VERSION ""

NS_ :

BS_:

BU_: Acquisition_Board2 Acquisition_Board3 Acquisition_Board5 Acquisition_Board6 Acquisition_Board7 Acquisition_Board8 VCU PDM BMS ICD Data_Station Acquisition_Board1

BO_ 3221225472 VECTOR__INDEPENDENT_SIG_MSG: 0 Vector__XXX
 SG_ NewSignal_0017 : 32|8@1+ (1,0) [0|0] "" Vector__XXX
 SG_ NewSignal_0016 : 48|16@1+ (0.1,0) [0|0] "" Vector__XXX
 SG_ SUSP_R : 0|16@1+ (0.1,0) [0|0] "mm" Vector__XXX
 SG_ SUSP_L : 16|16@1+ (0.1,0) [0|0] "mm" Vector__XXX
 SG_ NTC_3 : 32|16@1- (0.1,0) [0|0] "ºC" Vector__XXX
 SG_ SPD_WHEEL : 0|16@1+ (0.1,0) [0|0] "km/h" Vector__XXX
 SG_ SPD_WHEEL : 0|16@1+ (0.1,0) [0|0] "km/h" Vector__XXX
 SG_ SPD_WHEEL : 0|16@1+ (0.1,0) [0|0] "km/h" Vector__XXX
 SG_ SPD_WHEEL : 0|16@1+ (0.1,0) [0|0] "km/h" Vector__XXX
 SG_ TIRE_TEMP : 0|16@1- (0.1,0) [0|0] "ºC"  Data_Station
 SG_ BRAKE_TEMP : 16|16@1- (0.1,0) [0|0] "ºC"  Data_Station
 SG_ TIRE_TEMP : 0|16@1- (0.1,0) [0|0] "ºC"  Data_Station
 SG_ BRAKE_TEMP : 16|16@1- (0.1,0) [0|0] "ºC"  Data_Station
 SG_ TIRE_TEMP : 0|16@1- (0.1,0) [0|0] "ºC"  Data_Station
 SG_ BRAKE_TEMP : 16|16@1- (0.1,0) [0|0] "ºC"  Data_Station

BO_ 48 AQT2: 4 Acquisition_Board2
 SG_ FRONT_LEFT_WHEEL_RPM : 0|16@1+ (1,0) [0|0] "RPM"  Data_Station
 SG_ FRONT_RIGHT_WHEEL_RPM : 16|16@1+ (1,0) [0|0] "RPM"  Data_Station

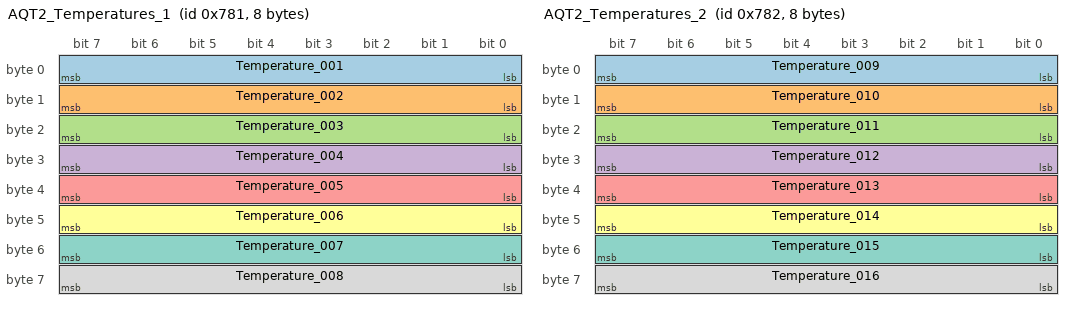
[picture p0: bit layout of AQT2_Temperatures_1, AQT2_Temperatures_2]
BO_ 1921 AQT2_Temperatures_1: 8 Acquisition_Board2
 SG_ Temperature_001 : 0|8@1+ (1,30) [30|285] "degC"  Data_Station
 SG_ Temperature_002 : 8|8@1+ (1,30) [30|285] "degC"  Data_Station
 SG_ Temperature_003 : 16|8@1+ (1,30) [30|285] "degC"  Data_Station
 SG_ Temperature_004 : 24|8@1+ (1,30) [30|285] "degC"  Data_Station
 SG_ Temperature_005 : 32|8@1+ (1,30) [30|285] "degC"  Data_Station
 SG_ Temperature_006 : 40|8@1+ (1,30) [30|285] "degC"  Data_Station
 SG_ Temperature_007 : 48|8@1+ (1,30) [30|285] "degC"  Data_Station
 SG_ Temperature_008 : 56|8@1+ (1,30) [30|285] "degC"  Data_Station

BO_ 1922 AQT2_Temperatures_2: 8 Acquisition_Board2
 SG_ Temperature_009 : 0|8@1+ (1,30) [30|285] "degC"  Data_Station
 SG_ Temperature_010 : 8|8@1+ (1,30) [30|285] "degC"  Data_Station
 SG_ Temperature_011 : 16|8@1+ (1,30) [30|285] "degC"  Data_Station
 SG_ Temperature_012 : 24|8@1+ (1,30) [30|285] "degC"  Data_Station
 SG_ Temperature_013 : 32|8@1+ (1,30) [30|285] "degC"  Data_Station
 SG_ Temperature_014 : 40|8@1+ (1,30) [30|285] "degC"  Data_Station
 SG_ Temperature_015 : 48|8@1+ (1,30) [30|285] "degC"  Data_Station
 SG_ Temperature_016 : 56|8@1+ (1,30) [30|285] "degC"  Data_Station

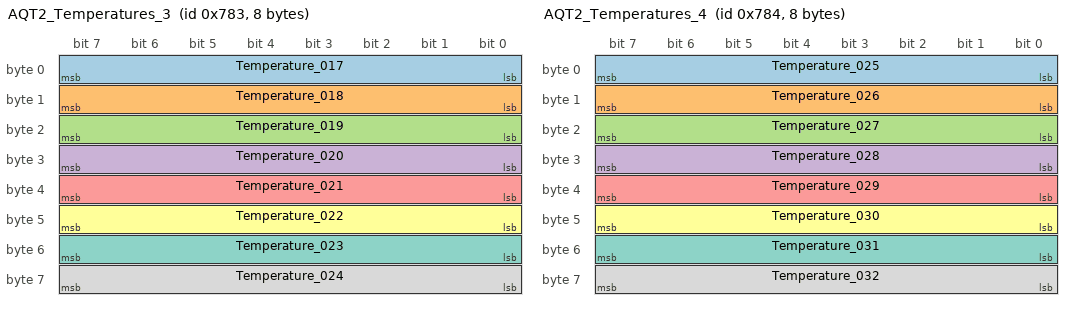
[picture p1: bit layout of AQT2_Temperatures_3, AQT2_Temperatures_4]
BO_ 1923 AQT2_Temperatures_3: 8 Acquisition_Board2
 SG_ Temperature_017 : 0|8@1+ (1,30) [30|285] "degC"  Data_Station
 SG_ Temperature_018 : 8|8@1+ (1,30) [30|285] "degC"  Data_Station
 SG_ Temperature_019 : 16|8@1+ (1,30) [30|285] "degC"  Data_Station
 SG_ Temperature_020 : 24|8@1+ (1,30) [30|285] "degC"  Data_Station
 SG_ Temperature_021 : 32|8@1+ (1,30) [30|285] "degC"  Data_Station
 SG_ Temperature_022 : 40|8@1+ (1,30) [30|285] "degC"  Data_Station
 SG_ Temperature_023 : 48|8@1+ (1,30) [30|285] "degC"  Data_Station
 SG_ Temperature_024 : 56|8@1+ (1,30) [30|285] "degC"  Data_Station

BO_ 1924 AQT2_Temperatures_4: 8 Acquisition_Board2
 SG_ Temperature_025 : 0|8@1+ (1,30) [30|285] "degC"  Data_Station
 SG_ Temperature_026 : 8|8@1+ (1,30) [30|285] "degC"  Data_Station
 SG_ Temperature_027 : 16|8@1+ (1,30) [30|285] "degC"  Data_Station
 SG_ Temperature_028 : 24|8@1+ (1,30) [30|285] "degC"  Data_Station
 SG_ Temperature_029 : 32|8@1+ (1,30) [30|285] "degC"  Data_Station
 SG_ Temperature_030 : 40|8@1+ (1,30) [30|285] "degC"  Data_Station
 SG_ Temperature_031 : 48|8@1+ (1,30) [30|285] "degC"  Data_Station
 SG_ Temperature_032 : 56|8@1+ (1,30) [30|285] "degC"  Data_Station

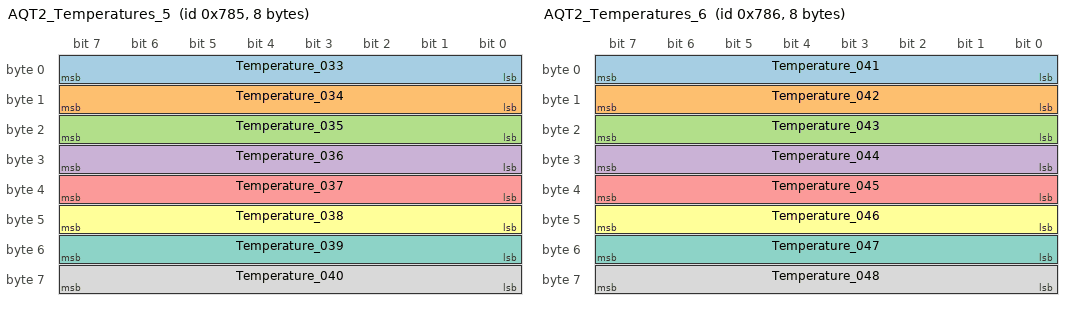
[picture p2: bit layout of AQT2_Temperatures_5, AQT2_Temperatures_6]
BO_ 1925 AQT2_Temperatures_5: 8 Acquisition_Board2
 SG_ Temperature_033 : 0|8@1+ (1,30) [30|285] "degC"  Data_Station
 SG_ Temperature_034 : 8|8@1+ (1,30) [30|285] "degC"  Data_Station
 SG_ Temperature_035 : 16|8@1+ (1,30) [30|285] "degC"  Data_Station
 SG_ Temperature_036 : 24|8@1+ (1,30) [30|285] "degC"  Data_Station
 SG_ Temperature_037 : 32|8@1+ (1,30) [30|285] "degC"  Data_Station
 SG_ Temperature_038 : 40|8@1+ (1,30) [30|285] "degC"  Data_Station
 SG_ Temperature_039 : 48|8@1+ (1,30) [30|285] "degC"  Data_Station
 SG_ Temperature_040 : 56|8@1+ (1,30) [30|285] "degC"  Data_Station

BO_ 1926 AQT2_Temperatures_6: 8 Acquisition_Board2
 SG_ Temperature_041 : 0|8@1+ (1,30) [30|285] "degC"  Data_Station
 SG_ Temperature_042 : 8|8@1+ (1,30) [30|285] "degC"  Data_Station
 SG_ Temperature_043 : 16|8@1+ (1,30) [30|285] "degC"  Data_Station
 SG_ Temperature_044 : 24|8@1+ (1,30) [30|285] "degC"  Data_Station
 SG_ Temperature_045 : 32|8@1+ (1,30) [30|285] "degC"  Data_Station
 SG_ Temperature_046 : 40|8@1+ (1,30) [30|285] "degC"  Data_Station
 SG_ Temperature_047 : 48|8@1+ (1,30) [30|285] "degC"  Data_Station
 SG_ Temperature_048 : 56|8@1+ (1,30) [30|285] "degC"  Data_Station

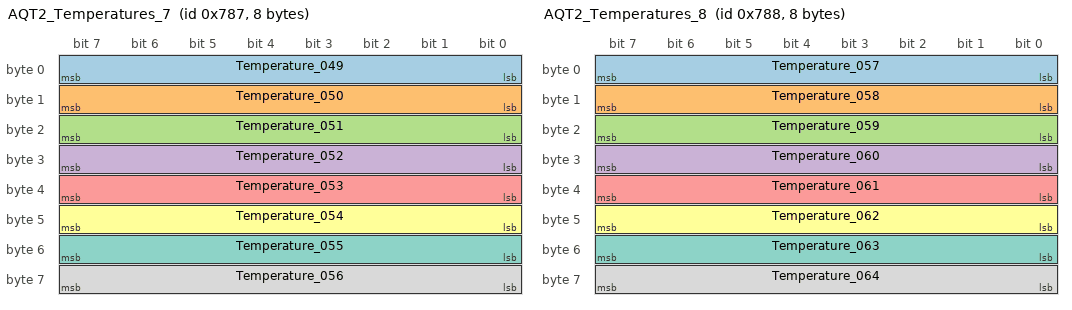
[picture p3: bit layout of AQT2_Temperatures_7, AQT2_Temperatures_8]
BO_ 1927 AQT2_Temperatures_7: 8 Acquisition_Board2
 SG_ Temperature_049 : 0|8@1+ (1,30) [30|285] "degC"  Data_Station
 SG_ Temperature_050 : 8|8@1+ (1,30) [30|285] "degC"  Data_Station
 SG_ Temperature_051 : 16|8@1+ (1,30) [30|285] "degC"  Data_Station
 SG_ Temperature_052 : 24|8@1+ (1,30) [30|285] "degC"  Data_Station
 SG_ Temperature_053 : 32|8@1+ (1,30) [30|285] "degC"  Data_Station
 SG_ Temperature_054 : 40|8@1+ (1,30) [30|285] "degC"  Data_Station
 SG_ Temperature_055 : 48|8@1+ (1,30) [30|285] "degC"  Data_Station
 SG_ Temperature_056 : 56|8@1+ (1,30) [30|285] "degC"  Data_Station

BO_ 1928 AQT2_Temperatures_8: 8 Acquisition_Board2
 SG_ Temperature_057 : 0|8@1+ (1,30) [30|285] "degC"  Data_Station
 SG_ Temperature_058 : 8|8@1+ (1,30) [30|285] "degC"  Data_Station
 SG_ Temperature_059 : 16|8@1+ (1,30) [30|285] "degC"  Data_Station
 SG_ Temperature_060 : 24|8@1+ (1,30) [30|285] "degC"  Data_Station
 SG_ Temperature_061 : 32|8@1+ (1,30) [30|285] "degC"  Data_Station
 SG_ Temperature_062 : 40|8@1+ (1,30) [30|285] "degC"  Data_Station
 SG_ Temperature_063 : 48|8@1+ (1,30) [30|285] "degC"  Data_Station
 SG_ Temperature_064 : 56|8@1+ (1,30) [30|285] "degC"  Data_Station

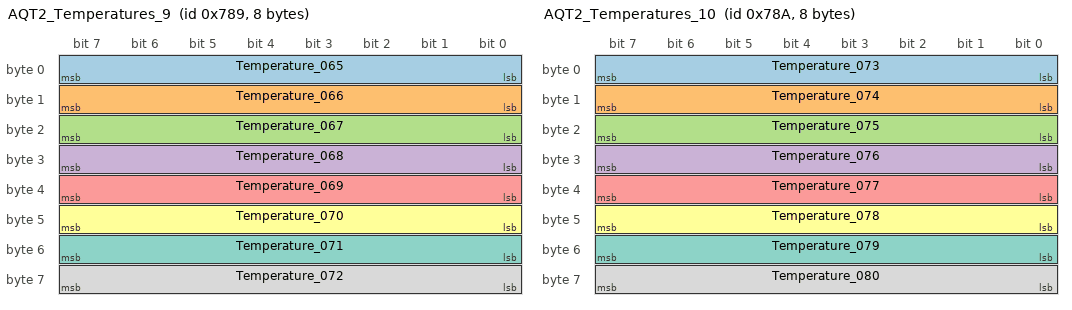
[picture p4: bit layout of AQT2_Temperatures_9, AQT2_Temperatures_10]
BO_ 1929 AQT2_Temperatures_9: 8 Acquisition_Board2
 SG_ Temperature_065 : 0|8@1+ (1,30) [30|285] "degC"  Data_Station
 SG_ Temperature_066 : 8|8@1+ (1,30) [30|285] "degC"  Data_Station
 SG_ Temperature_067 : 16|8@1+ (1,30) [30|285] "degC"  Data_Station
 SG_ Temperature_068 : 24|8@1+ (1,30) [30|285] "degC"  Data_Station
 SG_ Temperature_069 : 32|8@1+ (1,30) [30|285] "degC"  Data_Station
 SG_ Temperature_070 : 40|8@1+ (1,30) [30|285] "degC"  Data_Station
 SG_ Temperature_071 : 48|8@1+ (1,30) [30|285] "degC"  Data_Station
 SG_ Temperature_072 : 56|8@1+ (1,30) [30|285] "degC"  Data_Station

BO_ 1930 AQT2_Temperatures_10: 8 Acquisition_Board2
 SG_ Temperature_073 : 0|8@1+ (1,30) [30|285] "degC"  Data_Station
 SG_ Temperature_074 : 8|8@1+ (1,30) [30|285] "degC"  Data_Station
 SG_ Temperature_075 : 16|8@1+ (1,30) [30|285] "degC"  Data_Station
 SG_ Temperature_076 : 24|8@1+ (1,30) [30|285] "degC"  Data_Station
 SG_ Temperature_077 : 32|8@1+ (1,30) [30|285] "degC"  Data_Station
 SG_ Temperature_078 : 40|8@1+ (1,30) [30|285] "degC"  Data_Station
 SG_ Temperature_079 : 48|8@1+ (1,30) [30|285] "degC"  Data_Station
 SG_ Temperature_080 : 56|8@1+ (1,30) [30|285] "degC"  Data_Station

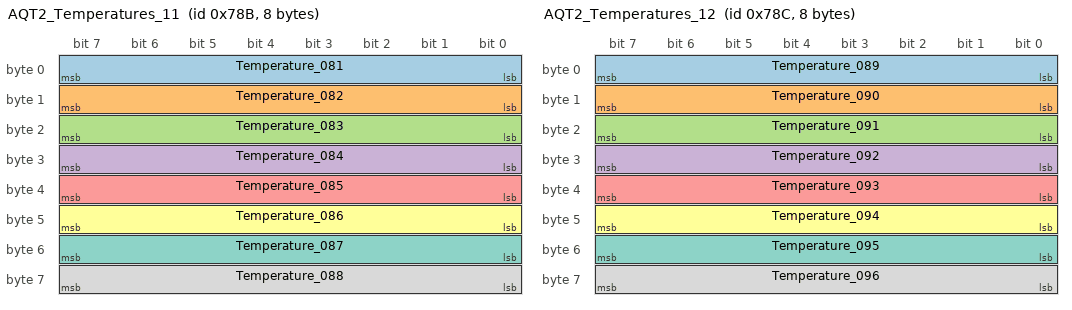
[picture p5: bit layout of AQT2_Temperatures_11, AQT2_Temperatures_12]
BO_ 1931 AQT2_Temperatures_11: 8 Acquisition_Board2
 SG_ Temperature_081 : 0|8@1+ (1,30) [30|285] "degC"  Data_Station
 SG_ Temperature_082 : 8|8@1+ (1,30) [30|285] "degC"  Data_Station
 SG_ Temperature_083 : 16|8@1+ (1,30) [30|285] "degC"  Data_Station
 SG_ Temperature_084 : 24|8@1+ (1,30) [30|285] "degC"  Data_Station
 SG_ Temperature_085 : 32|8@1+ (1,30) [30|285] "degC"  Data_Station
 SG_ Temperature_086 : 40|8@1+ (1,30) [30|285] "degC"  Data_Station
 SG_ Temperature_087 : 48|8@1+ (1,30) [30|285] "degC"  Data_Station
 SG_ Temperature_088 : 56|8@1+ (1,30) [30|285] "degC"  Data_Station

BO_ 1932 AQT2_Temperatures_12: 8 Acquisition_Board2
 SG_ Temperature_089 : 0|8@1+ (1,30) [30|285] "degC"  Data_Station
 SG_ Temperature_090 : 8|8@1+ (1,30) [30|285] "degC"  Data_Station
 SG_ Temperature_091 : 16|8@1+ (1,30) [30|285] "degC"  Data_Station
 SG_ Temperature_092 : 24|8@1+ (1,30) [30|285] "degC"  Data_Station
 SG_ Temperature_093 : 32|8@1+ (1,30) [30|285] "degC"  Data_Station
 SG_ Temperature_094 : 40|8@1+ (1,30) [30|285] "degC"  Data_Station
 SG_ Temperature_095 : 48|8@1+ (1,30) [30|285] "degC"  Data_Station
 SG_ Temperature_096 : 56|8@1+ (1,30) [30|285] "degC"  Data_Station

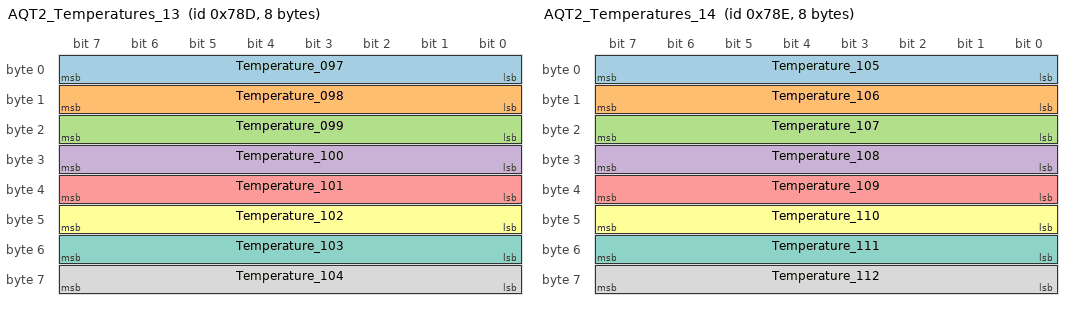
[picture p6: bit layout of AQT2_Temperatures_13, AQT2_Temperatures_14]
BO_ 1933 AQT2_Temperatures_13: 8 Acquisition_Board2
 SG_ Temperature_097 : 0|8@1+ (1,30) [30|285] "degC"  Data_Station
 SG_ Temperature_098 : 8|8@1+ (1,30) [30|285] "degC"  Data_Station
 SG_ Temperature_099 : 16|8@1+ (1,30) [30|285] "degC"  Data_Station
 SG_ Temperature_100 : 24|8@1+ (1,30) [30|285] "degC"  Data_Station
 SG_ Temperature_101 : 32|8@1+ (1,30) [30|285] "degC"  Data_Station
 SG_ Temperature_102 : 40|8@1+ (1,30) [30|285] "degC"  Data_Station
 SG_ Temperature_103 : 48|8@1+ (1,30) [30|285] "degC"  Data_Station
 SG_ Temperature_104 : 56|8@1+ (1,30) [30|285] "degC"  Data_Station

BO_ 1934 AQT2_Temperatures_14: 8 Acquisition_Board2
 SG_ Temperature_105 : 0|8@1+ (1,30) [30|285] "degC"  Data_Station
 SG_ Temperature_106 : 8|8@1+ (1,30) [30|285] "degC"  Data_Station
 SG_ Temperature_107 : 16|8@1+ (1,30) [30|285] "degC"  Data_Station
 SG_ Temperature_108 : 24|8@1+ (1,30) [30|285] "degC"  Data_Station
 SG_ Temperature_109 : 32|8@1+ (1,30) [30|285] "degC"  Data_Station
 SG_ Temperature_110 : 40|8@1+ (1,30) [30|285] "degC"  Data_Station
 SG_ Temperature_111 : 48|8@1+ (1,30) [30|285] "degC"  Data_Station
 SG_ Temperature_112 : 56|8@1+ (1,30) [30|285] "degC"  Data_Station

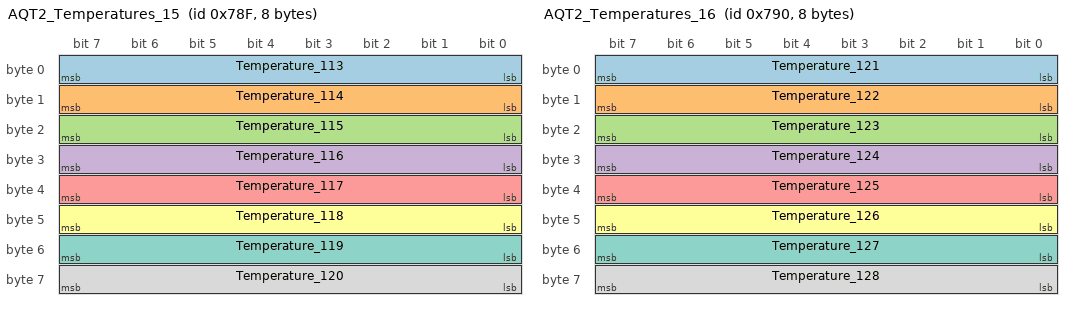
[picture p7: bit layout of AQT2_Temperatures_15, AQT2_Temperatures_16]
BO_ 1935 AQT2_Temperatures_15: 8 Acquisition_Board2
 SG_ Temperature_113 : 0|8@1+ (1,30) [30|285] "degC"  Data_Station
 SG_ Temperature_114 : 8|8@1+ (1,30) [30|285] "degC"  Data_Station
 SG_ Temperature_115 : 16|8@1+ (1,30) [30|285] "degC"  Data_Station
 SG_ Temperature_116 : 24|8@1+ (1,30) [30|285] "degC"  Data_Station
 SG_ Temperature_117 : 32|8@1+ (1,30) [30|285] "degC"  Data_Station
 SG_ Temperature_118 : 40|8@1+ (1,30) [30|285] "degC"  Data_Station
 SG_ Temperature_119 : 48|8@1+ (1,30) [30|285] "degC"  Data_Station
 SG_ Temperature_120 : 56|8@1+ (1,30) [30|285] "degC"  Data_Station

BO_ 1936 AQT2_Temperatures_16: 8 Acquisition_Board2
 SG_ Temperature_121 : 0|8@1+ (1,30) [30|285] "degC"  Data_Station
 SG_ Temperature_122 : 8|8@1+ (1,30) [30|285] "degC"  Data_Station
 SG_ Temperature_123 : 16|8@1+ (1,30) [30|285] "degC"  Data_Station
 SG_ Temperature_124 : 24|8@1+ (1,30) [30|285] "degC"  Data_Station
 SG_ Temperature_125 : 32|8@1+ (1,30) [30|285] "degC"  Data_Station
 SG_ Temperature_126 : 40|8@1+ (1,30) [30|285] "degC"  Data_Station
 SG_ Temperature_127 : 48|8@1+ (1,30) [30|285] "degC"  Data_Station
 SG_ Temperature_128 : 56|8@1+ (1,30) [30|285] "degC"  Data_Station

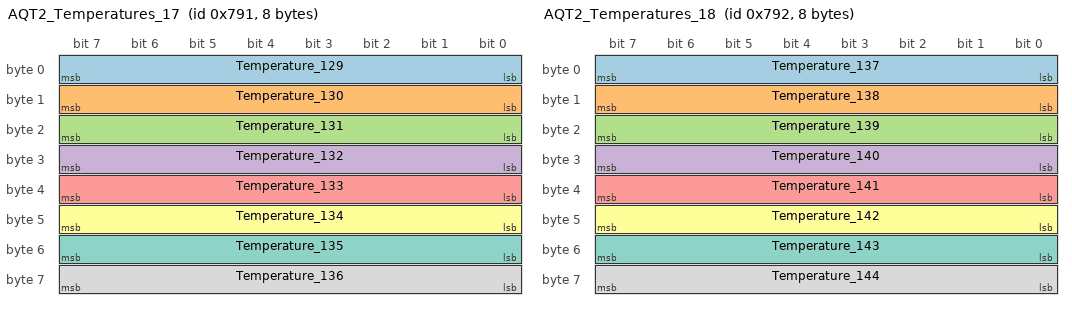
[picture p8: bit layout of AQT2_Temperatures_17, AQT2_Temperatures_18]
BO_ 1937 AQT2_Temperatures_17: 8 Acquisition_Board2
 SG_ Temperature_129 : 0|8@1+ (1,30) [30|285] "degC"  Data_Station
 SG_ Temperature_130 : 8|8@1+ (1,30) [30|285] "degC"  Data_Station
 SG_ Temperature_131 : 16|8@1+ (1,30) [30|285] "degC"  Data_Station
 SG_ Temperature_132 : 24|8@1+ (1,30) [30|285] "degC"  Data_Station
 SG_ Temperature_133 : 32|8@1+ (1,30) [30|285] "degC"  Data_Station
 SG_ Temperature_134 : 40|8@1+ (1,30) [30|285] "degC"  Data_Station
 SG_ Temperature_135 : 48|8@1+ (1,30) [30|285] "degC"  Data_Station
 SG_ Temperature_136 : 56|8@1+ (1,30) [30|285] "degC"  Data_Station

BO_ 1938 AQT2_Temperatures_18: 8 Acquisition_Board2
 SG_ Temperature_137 : 0|8@1+ (1,30) [30|285] "degC"  Data_Station
 SG_ Temperature_138 : 8|8@1+ (1,30) [30|285] "degC"  Data_Station
 SG_ Temperature_139 : 16|8@1+ (1,30) [30|285] "degC"  Data_Station
 SG_ Temperature_140 : 24|8@1+ (1,30) [30|285] "degC"  Data_Station
 SG_ Temperature_141 : 32|8@1+ (1,30) [30|285] "degC"  Data_Station
 SG_ Temperature_142 : 40|8@1+ (1,30) [30|285] "degC"  Data_Station
 SG_ Temperature_143 : 48|8@1+ (1,30) [30|285] "degC"  Data_Station
 SG_ Temperature_144 : 56|8@1+ (1,30) [30|285] "degC"  Data_Station

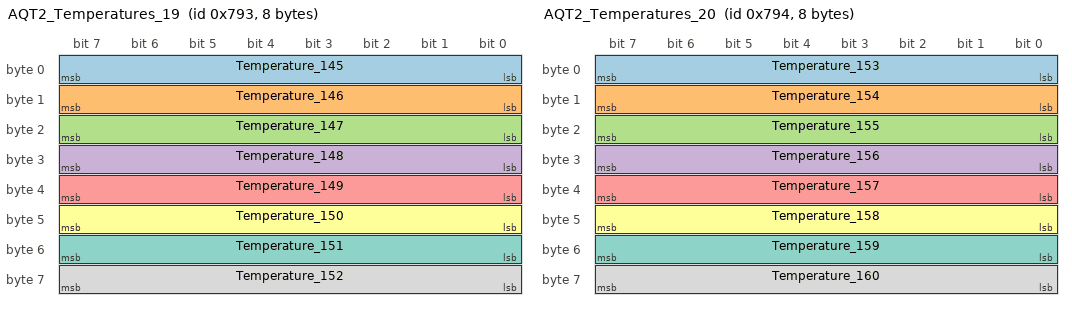
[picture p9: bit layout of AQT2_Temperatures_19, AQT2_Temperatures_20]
BO_ 1939 AQT2_Temperatures_19: 8 Acquisition_Board2
 SG_ Temperature_145 : 0|8@1+ (1,30) [30|285] "degC"  Data_Station
 SG_ Temperature_146 : 8|8@1+ (1,30) [30|285] "degC"  Data_Station
 SG_ Temperature_147 : 16|8@1+ (1,30) [30|285] "degC"  Data_Station
 SG_ Temperature_148 : 24|8@1+ (1,30) [30|285] "degC"  Data_Station
 SG_ Temperature_149 : 32|8@1+ (1,30) [30|285] "degC"  Data_Station
 SG_ Temperature_150 : 40|8@1+ (1,30) [30|285] "degC"  Data_Station
 SG_ Temperature_151 : 48|8@1+ (1,30) [30|285] "degC"  Data_Station
 SG_ Temperature_152 : 56|8@1+ (1,30) [30|285] "degC"  Data_Station

BO_ 1940 AQT2_Temperatures_20: 8 Acquisition_Board2
 SG_ Temperature_153 : 0|8@1+ (1,30) [30|285] "degC"  Data_Station
 SG_ Temperature_154 : 8|8@1+ (1,30) [30|285] "degC"  Data_Station
 SG_ Temperature_155 : 16|8@1+ (1,30) [30|285] "degC"  Data_Station
 SG_ Temperature_156 : 24|8@1+ (1,30) [30|285] "degC"  Data_Station
 SG_ Temperature_157 : 32|8@1+ (1,30) [30|285] "degC"  Data_Station
 SG_ Temperature_158 : 40|8@1+ (1,30) [30|285] "degC"  Data_Station
 SG_ Temperature_159 : 48|8@1+ (1,30) [30|285] "degC"  Data_Station
 SG_ Temperature_160 : 56|8@1+ (1,30) [30|285] "degC"  Data_Station

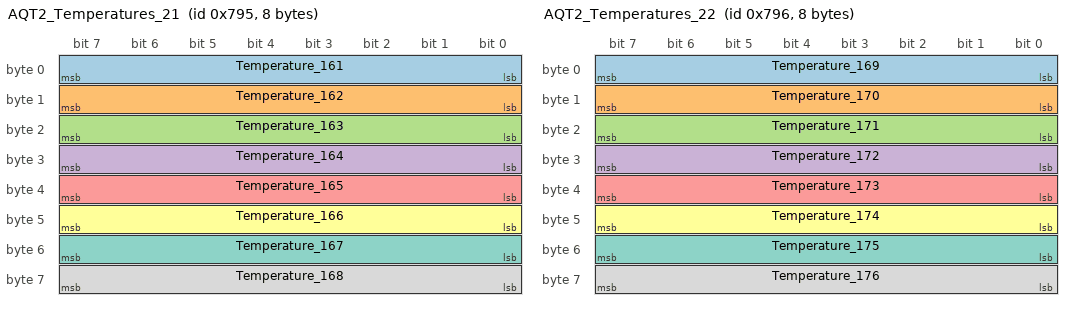
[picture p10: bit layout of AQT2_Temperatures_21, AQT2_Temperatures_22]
BO_ 1941 AQT2_Temperatures_21: 8 Acquisition_Board2
 SG_ Temperature_161 : 0|8@1+ (1,30) [30|285] "degC"  Data_Station
 SG_ Temperature_162 : 8|8@1+ (1,30) [30|285] "degC"  Data_Station
 SG_ Temperature_163 : 16|8@1+ (1,30) [30|285] "degC"  Data_Station
 SG_ Temperature_164 : 24|8@1+ (1,30) [30|285] "degC"  Data_Station
 SG_ Temperature_165 : 32|8@1+ (1,30) [30|285] "degC"  Data_Station
 SG_ Temperature_166 : 40|8@1+ (1,30) [30|285] "degC"  Data_Station
 SG_ Temperature_167 : 48|8@1+ (1,30) [30|285] "degC"  Data_Station
 SG_ Temperature_168 : 56|8@1+ (1,30) [30|285] "degC"  Data_Station

BO_ 1942 AQT2_Temperatures_22: 8 Acquisition_Board2
 SG_ Temperature_169 : 0|8@1+ (1,30) [30|285] "degC"  Data_Station
 SG_ Temperature_170 : 8|8@1+ (1,30) [30|285] "degC"  Data_Station
 SG_ Temperature_171 : 16|8@1+ (1,30) [30|285] "degC"  Data_Station
 SG_ Temperature_172 : 24|8@1+ (1,30) [30|285] "degC"  Data_Station
 SG_ Temperature_173 : 32|8@1+ (1,30) [30|285] "degC"  Data_Station
 SG_ Temperature_174 : 40|8@1+ (1,30) [30|285] "degC"  Data_Station
 SG_ Temperature_175 : 48|8@1+ (1,30) [30|285] "degC"  Data_Station
 SG_ Temperature_176 : 56|8@1+ (1,30) [30|285] "degC"  Data_Station

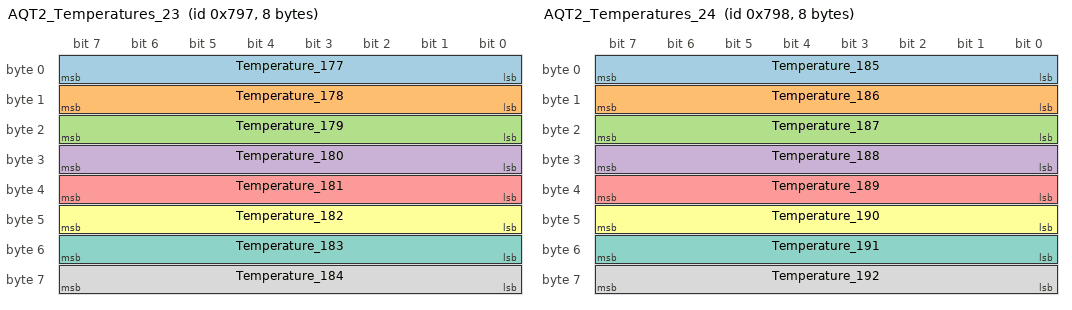
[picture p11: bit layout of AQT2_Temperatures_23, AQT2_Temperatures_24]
BO_ 1943 AQT2_Temperatures_23: 8 Acquisition_Board2
 SG_ Temperature_177 : 0|8@1+ (1,30) [30|285] "degC"  Data_Station
 SG_ Temperature_178 : 8|8@1+ (1,30) [30|285] "degC"  Data_Station
 SG_ Temperature_179 : 16|8@1+ (1,30) [30|285] "degC"  Data_Station
 SG_ Temperature_180 : 24|8@1+ (1,30) [30|285] "degC"  Data_Station
 SG_ Temperature_181 : 32|8@1+ (1,30) [30|285] "degC"  Data_Station
 SG_ Temperature_182 : 40|8@1+ (1,30) [30|285] "degC"  Data_Station
 SG_ Temperature_183 : 48|8@1+ (1,30) [30|285] "degC"  Data_Station
 SG_ Temperature_184 : 56|8@1+ (1,30) [30|285] "degC"  Data_Station

BO_ 1944 AQT2_Temperatures_24: 8 Acquisition_Board2
 SG_ Temperature_185 : 0|8@1+ (1,30) [30|285] "degC"  Data_Station
 SG_ Temperature_186 : 8|8@1+ (1,30) [30|285] "degC"  Data_Station
 SG_ Temperature_187 : 16|8@1+ (1,30) [30|285] "degC"  Data_Station
 SG_ Temperature_188 : 24|8@1+ (1,30) [30|285] "degC"  Data_Station
 SG_ Temperature_189 : 32|8@1+ (1,30) [30|285] "degC"  Data_Station
 SG_ Temperature_190 : 40|8@1+ (1,30) [30|285] "degC"  Data_Station
 SG_ Temperature_191 : 48|8@1+ (1,30) [30|285] "degC"  Data_Station
 SG_ Temperature_192 : 56|8@1+ (1,30) [30|285] "degC"  Data_Station

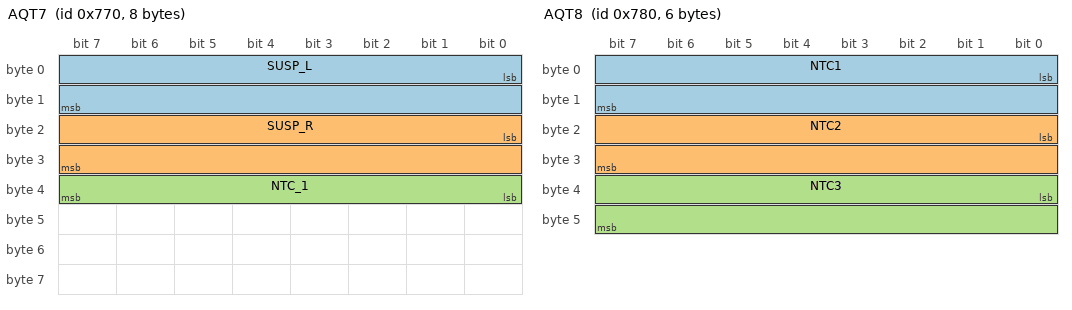
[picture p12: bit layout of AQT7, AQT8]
BO_ 1904 AQT7: 8 Acquisition_Board7
 SG_ SUSP_L : 0|16@1- (0.1,0) [0|0] "mm"  Data_Station
 SG_ SUSP_R : 16|16@1- (0.1,0) [0|0] "mm"  Data_Station
 SG_ NTC_1 : 32|8@1+ (1,0) [0|0] "ºC" Vector__XXX

BO_ 1920 AQT8: 6 Acquisition_Board8
 SG_ NTC1 : 0|16@1+ (0.1,0) [0|0] "ºC"  Data_Station
 SG_ NTC2 : 16|16@1+ (0.1,0) [0|0] "ºC"  Data_Station
 SG_ NTC3 : 32|16@1+ (0.1,0) [0|0] "ºC"  Data_Station

BO_ 1092 VCU_INV1_Temperatures: 8 VCU
 SG_ INV1_TempInverter : 7|16@0- (0.1,0) [-55|200] "ºC"  Data_Station
 SG_ INV1_TempMotor : 23|16@0- (0.1,0) [-55|200] "ºC"  Data_Station

BO_ 1093 VCU_INV2_Temperatures: 8 VCU
 SG_ INV2_TempInverter : 7|16@0- (0.1,0) [-55|200] "ºC"  Data_Station
 SG_ INV2_TempMotor : 23|16@0- (0.1,0) [-55|200] "ºC"  Data_Station

BO_ 528 PDM_LV: 2 PDM
 SG_ LV_Voltage_mV : 0|16@1+ (0.001,0) [0|0] ""  Data_Station

BO_ 544 PDM_Cooling: 8 PDM
 SG_ WaterPump_PWM : 0|8@1+ (1,0) [0|0] ""  Data_Station
 SG_ CoolingFan_PWM : 8|8@1+ (1,0) [0|0] ""  Data_Station

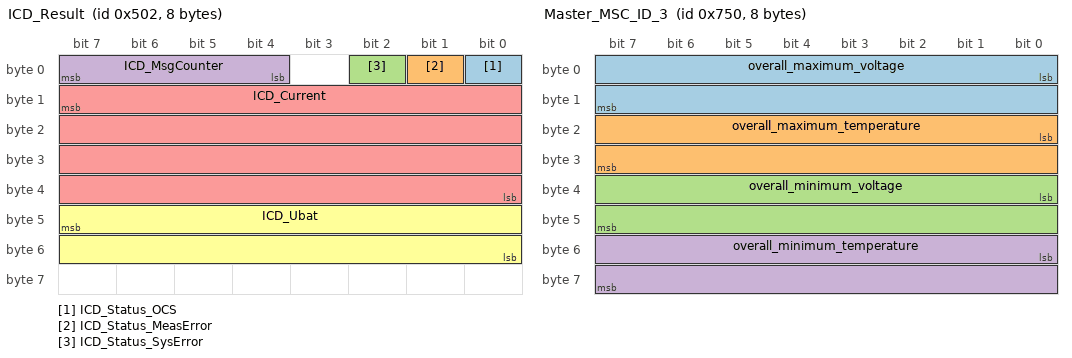
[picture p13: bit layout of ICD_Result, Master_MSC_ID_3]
BO_ 1282 ICD_Result: 8 ICD
 SG_ ICD_Status_OCS : 0|1@1+ (1,0) [0|1] ""  Data_Station
 SG_ ICD_Status_MeasError : 1|1@1+ (1,0) [0|1] ""  Data_Station
 SG_ ICD_Status_SysError : 2|1@1+ (1,0) [0|1] ""  Data_Station
 SG_ ICD_MsgCounter : 4|4@1+ (1,0) [0|15] ""  Data_Station
 SG_ ICD_Current : 15|32@0- (0.001,0) [-2500|2500] "A"  Data_Station
 SG_ ICD_Ubat : 47|16@0+ (0.001,0) [0|65.535] "V"  Data_Station

BO_ 1280 ICD_Request: 8 PDM
 SG_ Req_MuxID M : 0|8@1+ (1,0) [0|255] ""  ICD,Data_Station
 SG_ Req_OpMode m16 : 8|8@1+ (1,0) [0|2] ""  ICD,Data_Station
 SG_ Req_OpOutputRate m16 : 23|16@0+ (1,0) [0|65535] "ms"  ICD,Data_Station
 SG_ Req_OpInvertCurrent m16 : 32|1@1+ (1,0) [0|1] ""  ICD,Data_Station
 SG_ Req_AccessMode m17 : 8|8@1+ (1,0) [0|1] ""  ICD,Data_Station
 SG_ Req_AccessPw1 m17 : 16|8@1+ (1,0) [0|255] ""  ICD,Data_Station
 SG_ Req_AccessPw2 m17 : 24|8@1+ (1,0) [0|255] ""  ICD,Data_Station
 SG_ Req_AccessPw3 m17 : 32|8@1+ (1,0) [0|255] ""  ICD,Data_Station
 SG_ Req_AccessPw4 m17 : 40|8@1+ (1,0) [0|255] ""  ICD,Data_Station
 SG_ Req_AccessPw5 m17 : 48|8@1+ (1,0) [0|255] ""  ICD,Data_Station
 SG_ Req_AccessPw6 m17 : 56|8@1+ (1,0) [0|255] ""  ICD,Data_Station
 SG_ Req_Averaging m32 : 8|8@1+ (1,0) [0|255] ""  ICD,Data_Station
 SG_ Req_OCLimitPos m33 : 15|24@0+ (1,0) [0|16777215] "A"  ICD,Data_Station
 SG_ Req_OCLimitNeg m33 : 39|24@0+ (1,0) [0|16777215] "A"  ICD,Data_Station
 SG_ Req_CanBaudrate m34 : 8|8@1+ (1,0) [0|2] ""  ICD,Data_Station
 SG_ Req_CanMode m34 : 16|8@1+ (1,0) [0|1] ""  ICD,Data_Station
 SG_ Req_CanIdReq_SN m35 : 15|24@0+ (1,0) [0|16777215] ""  ICD,Data_Station
 SG_ Req_CanIdReq_ID m35 : 39|32@0+ (1,0) [0|536870911] ""  ICD,Data_Station
 SG_ Req_CanIdResp_SN m36 : 15|24@0+ (1,0) [0|16777215] ""  ICD,Data_Station
 SG_ Req_CanIdResp_ID m36 : 39|32@0+ (1,0) [0|536870911] ""  ICD,Data_Station
 SG_ Req_CanIdRes_SN m37 : 15|24@0+ (1,0) [0|16777215] ""  ICD,Data_Station
 SG_ Req_CanIdRes_ID m37 : 39|32@0+ (1,0) [0|536870911] ""  ICD,Data_Station
 SG_ Req_NewPw1 m38 : 8|8@1+ (1,0) [32|126] ""  ICD,Data_Station
 SG_ Req_NewPw2 m38 : 16|8@1+ (1,0) [32|126] ""  ICD,Data_Station
 SG_ Req_NewPw3 m38 : 24|8@1+ (1,0) [32|126] ""  ICD,Data_Station
 SG_ Req_NewPw4 m38 : 32|8@1+ (1,0) [32|126] ""  ICD,Data_Station
 SG_ Req_NewPw5 m38 : 40|8@1+ (1,0) [32|126] ""  ICD,Data_Station
 SG_ Req_NewPw6 m38 : 48|8@1+ (1,0) [32|126] ""  ICD,Data_Station
 SG_ Req_ResetOption m64 : 8|8@1+ (1,0) [1|2] ""  ICD,Data_Station
 SG_ Req_WakeTimer m65 : 8|1@1+ (1,0) [0|1] ""  ICD,Data_Station
 SG_ Req_WakeIThreshold m65 : 9|1@1+ (1,0) [0|1] ""  ICD,Data_Station
 SG_ Req_WakeAhThreshold m65 : 10|1@1+ (1,0) [0|1] ""  ICD,Data_Station
 SG_ Req_SleepTimer m65 : 23|16@0+ (1,0) [0|65000] "s"  ICD,Data_Station
 SG_ Req_SleepIThreshold m65 : 39|16@0+ (1,0) [0|250] "mA"  ICD,Data_Station
 SG_ Req_SleepAhThreshold m65 : 55|16@0+ (1,0) [0|65000] "mAs"  ICD,Data_Station

BO_ 1281 ICD_Response: 8 ICD
 SG_ Resp_MuxID M : 0|8@1+ (1,0) [0|255] ""  Data_Station
 SG_ Resp_Tchip m145 : 15|16@0- (0.1,0) [-40|125] "degC"  Data_Station
 SG_ Resp_Text m145 : 31|16@0- (0.1,0) [-40|125] "degC"  Data_Station
 SG_ Resp_AhCounter m146 : 15|32@0- (1,0) [-2147483648|2147483647] "mAs"  Data_Station
 SG_ Resp_OpMode m160 : 8|8@1+ (1,0) [0|2] ""  Data_Station
 SG_ Resp_OpOutputRate m160 : 23|16@0+ (1,0) [0|65535] "ms"  Data_Station
 SG_ Resp_OpInvertCurrent m160 : 32|1@1+ (1,0) [0|1] ""  Data_Station
 SG_ Resp_AccessMode m161 : 8|8@1+ (1,0) [0|1] ""  Data_Station
 SG_ Resp_Averaging m176 : 8|8@1+ (1,0) [0|255] ""  Data_Station
 SG_ Resp_OCLimitPos m177 : 15|24@0+ (1,0) [0|16777215] "A"  Data_Station
 SG_ Resp_OCLimitNeg m177 : 39|24@0+ (1,0) [0|16777215] "A"  Data_Station
 SG_ Resp_CanBaudrate m178 : 8|8@1+ (1,0) [0|2] ""  Data_Station
 SG_ Resp_CanMode m178 : 16|8@1+ (1,0) [0|1] ""  Data_Station
 SG_ Resp_CanIdReq_SN m179 : 15|24@0+ (1,0) [0|16777215] ""  Data_Station
 SG_ Resp_CanIdReq_ID m179 : 39|32@0+ (1,0) [0|536870911] ""  Data_Station
 SG_ Resp_CanIdResp_SN m180 : 15|24@0+ (1,0) [0|16777215] ""  Data_Station
 SG_ Resp_CanIdResp_ID m180 : 39|32@0+ (1,0) [0|536870911] ""  Data_Station
 SG_ Resp_CanIdRes_SN m181 : 15|24@0+ (1,0) [0|16777215] ""  Data_Station
 SG_ Resp_CanIdRes_ID m181 : 39|32@0+ (1,0) [0|536870911] ""  Data_Station
 SG_ Resp_Pw1 m182 : 8|8@1+ (1,0) [32|126] ""  Data_Station
 SG_ Resp_Pw2 m182 : 16|8@1+ (1,0) [32|126] ""  Data_Station
 SG_ Resp_Pw3 m182 : 24|8@1+ (1,0) [32|126] ""  Data_Station
 SG_ Resp_Pw4 m182 : 32|8@1+ (1,0) [32|126] ""  Data_Station
 SG_ Resp_Pw5 m182 : 40|8@1+ (1,0) [32|126] ""  Data_Station
 SG_ Resp_Pw6 m182 : 48|8@1+ (1,0) [32|126] ""  Data_Station
 SG_ Resp_ResetOption m208 : 8|8@1+ (1,0) [1|2] ""  Data_Station
 SG_ Resp_WakeTimer m209 : 8|1@1+ (1,0) [0|1] ""  Data_Station
 SG_ Resp_WakeIThreshold m209 : 9|1@1+ (1,0) [0|1] ""  Data_Station
 SG_ Resp_WakeAhThreshold m209 : 10|1@1+ (1,0) [0|1] ""  Data_Station
 SG_ Resp_SleepTimer m209 : 23|16@0+ (1,0) [0|65000] "s"  Data_Station
 SG_ Resp_SleepIThreshold m209 : 39|16@0+ (1,0) [0|250] "mA"  Data_Station
 SG_ Resp_SleepAhThreshold m209 : 55|16@0+ (1,0) [0|65000] "mAs"  Data_Station
 SG_ Resp_DevId_Frame m224 : 8|8@1+ (1,0) [0|3] ""  Data_Station
 SG_ Resp_DevId_Char1 m224 : 16|8@1+ (1,0) [0|255] ""  Data_Station
 SG_ Resp_DevId_Char2 m224 : 24|8@1+ (1,0) [0|255] ""  Data_Station
 SG_ Resp_DevId_Char3 m224 : 32|8@1+ (1,0) [0|255] ""  Data_Station
 SG_ Resp_DevId_Char4 m224 : 40|8@1+ (1,0) [0|255] ""  Data_Station
 SG_ Resp_DevId_Char5 m224 : 48|8@1+ (1,0) [0|255] ""  Data_Station
 SG_ Resp_FwMajor m225 : 8|8@1+ (1,-48) [0|9] ""  Data_Station
 SG_ Resp_FwMinor m225 : 16|8@1+ (1,-48) [0|9] ""  Data_Station
 SG_ Resp_FwRelease m225 : 24|8@1+ (1,-48) [0|9] ""  Data_Station
 SG_ Resp_SerialNumber m226 : 15|32@0+ (1,0) [0|4294967295] ""  Data_Station
 SG_ Resp_HwVer_Frame m227 : 8|8@1+ (1,0) [0|1] ""  Data_Station
 SG_ Resp_HwVer_Char1 m227 : 16|8@1+ (1,0) [0|255] ""  Data_Station
 SG_ Resp_HwVer_Char2 m227 : 24|8@1+ (1,0) [0|255] ""  Data_Station
 SG_ Resp_HwVer_Char3 m227 : 32|8@1+ (1,0) [0|255] ""  Data_Station
 SG_ Resp_HwVer_Char4 m227 : 40|8@1+ (1,0) [0|255] ""  Data_Station
 SG_ Resp_HwVer_Char5 m227 : 48|8@1+ (1,0) [0|255] ""  Data_Station
 SG_ Resp_HwVer_Char6 m227 : 56|8@1+ (1,0) [0|255] ""  Data_Station
 SG_ Resp_ArticleNumber m228 : 15|56@0+ (1,0) [0|7.2057594038E+16] ""  Data_Station
 SG_ Resp_Rev_Digit1 m229 : 32|8@1+ (1,-48) [0|9] ""  Data_Station
 SG_ Resp_Rev_Digit2 m229 : 40|8@1+ (1,-48) [0|9] ""  Data_Station
 SG_ Resp_Rev_Digit3 m229 : 48|8@1+ (1,-48) [0|9] ""  Data_Station
 SG_ Resp_Rev_Digit4 m229 : 56|8@1+ (1,-48) [0|9] ""  Data_Station
 SG_ Resp_UpTime m230 : 15|32@0+ (1,0) [0|4294967295] "min"  Data_Station
 SG_ Resp_Lifetime m231 : 15|32@0+ (1,0) [0|4294967295] "min"  Data_Station
 SG_ Resp_MS_AdcInterrupt m232 : 32|1@1+ (1,0) [0|1] ""  Data_Station
 SG_ Resp_MS_OverflowAdcCh1 m232 : 33|1@1+ (1,0) [0|1] ""  Data_Station
 SG_ Resp_MS_OverflowAdcCh2 m232 : 34|1@1+ (1,0) [0|1] ""  Data_Station
 SG_ Resp_MS_OverflowAdcCh3 m232 : 35|1@1+ (1,0) [0|1] ""  Data_Station
 SG_ Resp_MS_OpenCircuitI m232 : 36|1@1+ (1,0) [0|1] ""  Data_Station
 SG_ Resp_MS_OpenCircuitU m232 : 37|1@1+ (1,0) [0|1] ""  Data_Station
 SG_ Resp_MS_OpenCircuitTchip m232 : 38|1@1+ (1,0) [0|1] ""  Data_Station
 SG_ Resp_MS_OpenCircuitText m232 : 39|1@1+ (1,0) [0|1] ""  Data_Station
 SG_ Resp_MS_CalibrationData m232 : 24|1@1+ (1,0) [0|1] ""  Data_Station
 SG_ Resp_MS_OCSActive m232 : 25|1@1+ (1,0) [0|1] ""  Data_Station
 SG_ Resp_SS_CodeCrc m232 : 48|1@1+ (1,0) [0|1] ""  Data_Station
 SG_ Resp_SS_CalDataCrc m232 : 49|1@1+ (1,0) [0|1] ""  Data_Station
 SG_ Resp_SS_CanRx m232 : 50|1@1+ (1,0) [0|1] ""  Data_Station
 SG_ Resp_SS_CanTx m232 : 51|1@1+ (1,0) [0|1] ""  Data_Station
 SG_ Resp_SS_Overtemp m232 : 52|1@1+ (1,0) [0|1] ""  Data_Station
 SG_ Resp_SS_Undertemp m232 : 53|1@1+ (1,0) [0|1] ""  Data_Station
 SG_ Resp_SS_PowerFailure m232 : 54|1@1+ (1,0) [0|1] ""  Data_Station
 SG_ Resp_SS_SystemClock m232 : 55|1@1+ (1,0) [0|1] ""  Data_Station
 SG_ Resp_SS_SystemInit m232 : 40|1@1+ (1,0) [0|1] ""  Data_Station
 SG_ Resp_SS_Configuration m232 : 41|1@1+ (1,0) [0|1] ""  Data_Station
 SG_ Resp_SS_EepromRW m232 : 42|1@1+ (1,0) [0|1] ""  Data_Station
 SG_ Resp_SS_PowerOnReset m232 : 43|1@1+ (1,0) [0|1] ""  Data_Station
 SG_ Resp_SS_LowVoltageReset m232 : 44|1@1+ (1,0) [0|1] ""  Data_Station
 SG_ Resp_SS_ExtPinReset m232 : 45|1@1+ (1,0) [0|1] ""  Data_Station
 SG_ Resp_SS_ClockMonReset m232 : 46|1@1+ (1,0) [0|1] ""  Data_Station
 SG_ Resp_SS_CopWdReset m232 : 47|1@1+ (1,0) [0|1] ""  Data_Station
 SG_ Resp_EvtMeasType m235 : 8|8@1+ (1,0) [0|255] ""  Data_Station
 SG_ Resp_EvtSysType m235 : 16|8@1+ (1,0) [0|255] ""  Data_Station
 SG_ Resp_EvtMeasCount m235 : 31|16@0+ (1,0) [0|65535] ""  Data_Station
 SG_ Resp_EvtSysCount m235 : 47|16@0+ (1,0) [0|65535] ""  Data_Station

BO_ 1792 AQT1: 8 Acquisition_Board1
 SG_ Throtle_Percentage : 0|8@1+ (1,0) [0|0] "" Vector__XXX

BO_ 1872 Master_MSC_ID_3: 8 BMS
 SG_ overall_maximum_voltage : 0|16@1+ (0.001,0) [0|0] "V" Vector__XXX
 SG_ overall_maximum_temperature : 16|16@1+ (0.01,0) [0|0] "degC" Vector__XXX
 SG_ overall_minimum_voltage : 32|16@1+ (0.001,0) [0|0] "V" Vector__XXX
 SG_ overall_minimum_temperature : 48|16@1+ (0.01,0) [0|0] "degC" Vector__XXX

CM_ BU_ ICD "Isabellenhuette ISAscale ICD shunt current sensor (datasheet v1.3)";
CM_ BU_ Data_Station "RPi 5 CAN Shield";
CM_ BO_ 48 "AQT2 Repeater";
CM_ BO_ 1921 "16x12 thermal matrix, block 1/24. Row-major: 16 columns x 12 rows, zero-based row 0, columns 0..7. T_degC = raw + 30. Send all blocks from one frozen acquisition in ascending order; no acquisition counter in payload.";
CM_ BO_ 1922 "16x12 thermal matrix, block 2/24. Row-major: 16 columns x 12 rows, zero-based row 0, columns 8..15. T_degC = raw + 30. Send all blocks from one frozen acquisition in ascending order; no acquisition counter in payload.";
CM_ BO_ 1923 "16x12 thermal matrix, block 3/24. Row-major: 16 columns x 12 rows, zero-based row 1, columns 0..7. T_degC = raw + 30. Send all blocks from one frozen acquisition in ascending order; no acquisition counter in payload.";
CM_ BO_ 1924 "16x12 thermal matrix, block 4/24. Row-major: 16 columns x 12 rows, zero-based row 1, columns 8..15. T_degC = raw + 30. Send all blocks from one frozen acquisition in ascending order; no acquisition counter in payload.";
CM_ BO_ 1925 "16x12 thermal matrix, block 5/24. Row-major: 16 columns x 12 rows, zero-based row 2, columns 0..7. T_degC = raw + 30. Send all blocks from one frozen acquisition in ascending order; no acquisition counter in payload.";
CM_ BO_ 1926 "16x12 thermal matrix, block 6/24. Row-major: 16 columns x 12 rows, zero-based row 2, columns 8..15. T_degC = raw + 30. Send all blocks from one frozen acquisition in ascending order; no acquisition counter in payload.";
CM_ BO_ 1927 "16x12 thermal matrix, block 7/24. Row-major: 16 columns x 12 rows, zero-based row 3, columns 0..7. T_degC = raw + 30. Send all blocks from one frozen acquisition in ascending order; no acquisition counter in payload.";
CM_ BO_ 1928 "16x12 thermal matrix, block 8/24. Row-major: 16 columns x 12 rows, zero-based row 3, columns 8..15. T_degC = raw + 30. Send all blocks from one frozen acquisition in ascending order; no acquisition counter in payload.";
CM_ BO_ 1929 "16x12 thermal matrix, block 9/24. Row-major: 16 columns x 12 rows, zero-based row 4, columns 0..7. T_degC = raw + 30. Send all blocks from one frozen acquisition in ascending order; no acquisition counter in payload.";
CM_ BO_ 1930 "16x12 thermal matrix, block 10/24. Row-major: 16 columns x 12 rows, zero-based row 4, columns 8..15. T_degC = raw + 30. Send all blocks from one frozen acquisition in ascending order; no acquisition counter in payload.";
CM_ BO_ 1931 "16x12 thermal matrix, block 11/24. Row-major: 16 columns x 12 rows, zero-based row 5, columns 0..7. T_degC = raw + 30. Send all blocks from one frozen acquisition in ascending order; no acquisition counter in payload.";
CM_ BO_ 1932 "16x12 thermal matrix, block 12/24. Row-major: 16 columns x 12 rows, zero-based row 5, columns 8..15. T_degC = raw + 30. Send all blocks from one frozen acquisition in ascending order; no acquisition counter in payload.";
CM_ BO_ 1933 "16x12 thermal matrix, block 13/24. Row-major: 16 columns x 12 rows, zero-based row 6, columns 0..7. T_degC = raw + 30. Send all blocks from one frozen acquisition in ascending order; no acquisition counter in payload.";
CM_ BO_ 1934 "16x12 thermal matrix, block 14/24. Row-major: 16 columns x 12 rows, zero-based row 6, columns 8..15. T_degC = raw + 30. Send all blocks from one frozen acquisition in ascending order; no acquisition counter in payload.";
CM_ BO_ 1935 "16x12 thermal matrix, block 15/24. Row-major: 16 columns x 12 rows, zero-based row 7, columns 0..7. T_degC = raw + 30. Send all blocks from one frozen acquisition in ascending order; no acquisition counter in payload.";
CM_ BO_ 1936 "16x12 thermal matrix, block 16/24. Row-major: 16 columns x 12 rows, zero-based row 7, columns 8..15. T_degC = raw + 30. Send all blocks from one frozen acquisition in ascending order; no acquisition counter in payload.";
CM_ BO_ 1937 "16x12 thermal matrix, block 17/24. Row-major: 16 columns x 12 rows, zero-based row 8, columns 0..7. T_degC = raw + 30. Send all blocks from one frozen acquisition in ascending order; no acquisition counter in payload.";
CM_ BO_ 1938 "16x12 thermal matrix, block 18/24. Row-major: 16 columns x 12 rows, zero-based row 8, columns 8..15. T_degC = raw + 30. Send all blocks from one frozen acquisition in ascending order; no acquisition counter in payload.";
CM_ BO_ 1939 "16x12 thermal matrix, block 19/24. Row-major: 16 columns x 12 rows, zero-based row 9, columns 0..7. T_degC = raw + 30. Send all blocks from one frozen acquisition in ascending order; no acquisition counter in payload.";
CM_ BO_ 1940 "16x12 thermal matrix, block 20/24. Row-major: 16 columns x 12 rows, zero-based row 9, columns 8..15. T_degC = raw + 30. Send all blocks from one frozen acquisition in ascending order; no acquisition counter in payload.";
CM_ BO_ 1941 "16x12 thermal matrix, block 21/24. Row-major: 16 columns x 12 rows, zero-based row 10, columns 0..7. T_degC = raw + 30. Send all blocks from one frozen acquisition in ascending order; no acquisition counter in payload.";
CM_ BO_ 1942 "16x12 thermal matrix, block 22/24. Row-major: 16 columns x 12 rows, zero-based row 10, columns 8..15. T_degC = raw + 30. Send all blocks from one frozen acquisition in ascending order; no acquisition counter in payload.";
CM_ BO_ 1943 "16x12 thermal matrix, block 23/24. Row-major: 16 columns x 12 rows, zero-based row 11, columns 0..7. T_degC = raw + 30. Send all blocks from one frozen acquisition in ascending order; no acquisition counter in payload.";
CM_ BO_ 1944 "16x12 thermal matrix, block 24/24. Row-major: 16 columns x 12 rows, zero-based row 11, columns 8..15. T_degC = raw + 30. Send all blocks from one frozen acquisition in ascending order; no acquisition counter in payload.";
CM_ BO_ 1092 "0x444 - INV1 (left) temperatures from HV500 inverter";
CM_ SG_ 1092 INV1_TempInverter "Inverter semiconductor temperature";
CM_ SG_ 1092 INV1_TempMotor "Motor temperature measured by the inverter";
CM_ BO_ 1093 "0x445 - INV2 (right) temperatures from HV500 inverter";
CM_ SG_ 1093 INV2_TempInverter "Inverter semiconductor temperature";
CM_ SG_ 1093 INV2_TempMotor "Motor temperature measured by the inverter";
CM_ BO_ 1282 "Cyclic result frame (default 1 ms in continuous mode). No multiplexer.";
CM_ SG_ 1282 ICD_MsgCounter "Rolling counter 0x0..0xF (high nibble of D0).";
CM_ SG_ 1282 ICD_Current "Signed 32 bit, 1 mA/LSB. Byte order assumed big-endian (Motorola).";
CM_ SG_ 1282 ICD_Ubat "Supply voltage, unsigned 16 bit. 1 mV/LSB (verified on bench; datasheet 0.5 mV figure is resolution, not LSB).";
CM_ BO_ 1280 "Command frame (SET/GET/control), D0 = MUX ID. Get commands carry no payload.";
CM_ SG_ 1280 Req_AccessPw1 "Customer password byte 1 (default 0x30 = '0').";
CM_ BO_ 1281 "Response frame to requests, D0 = response MUX ID. Also carries startup messages (0xE0 x4, 0xE2, 0xE1).";
CM_ SG_ 1281 Resp_AhCounter "Ampere-hour counter in mAs (divide by 3.6e6 for Ah).";
CM_ SG_ 1281 Resp_DevId_Frame "Device ID is a 4-frame multiframe response (counter 0..3), ASCII chars e.g. ICD-A-0100-CAN2-12.";
CM_ SG_ 1281 Resp_HwVer_Frame "HW version is a 2-frame multiframe response (counter 0..1), ASCII chars.";
